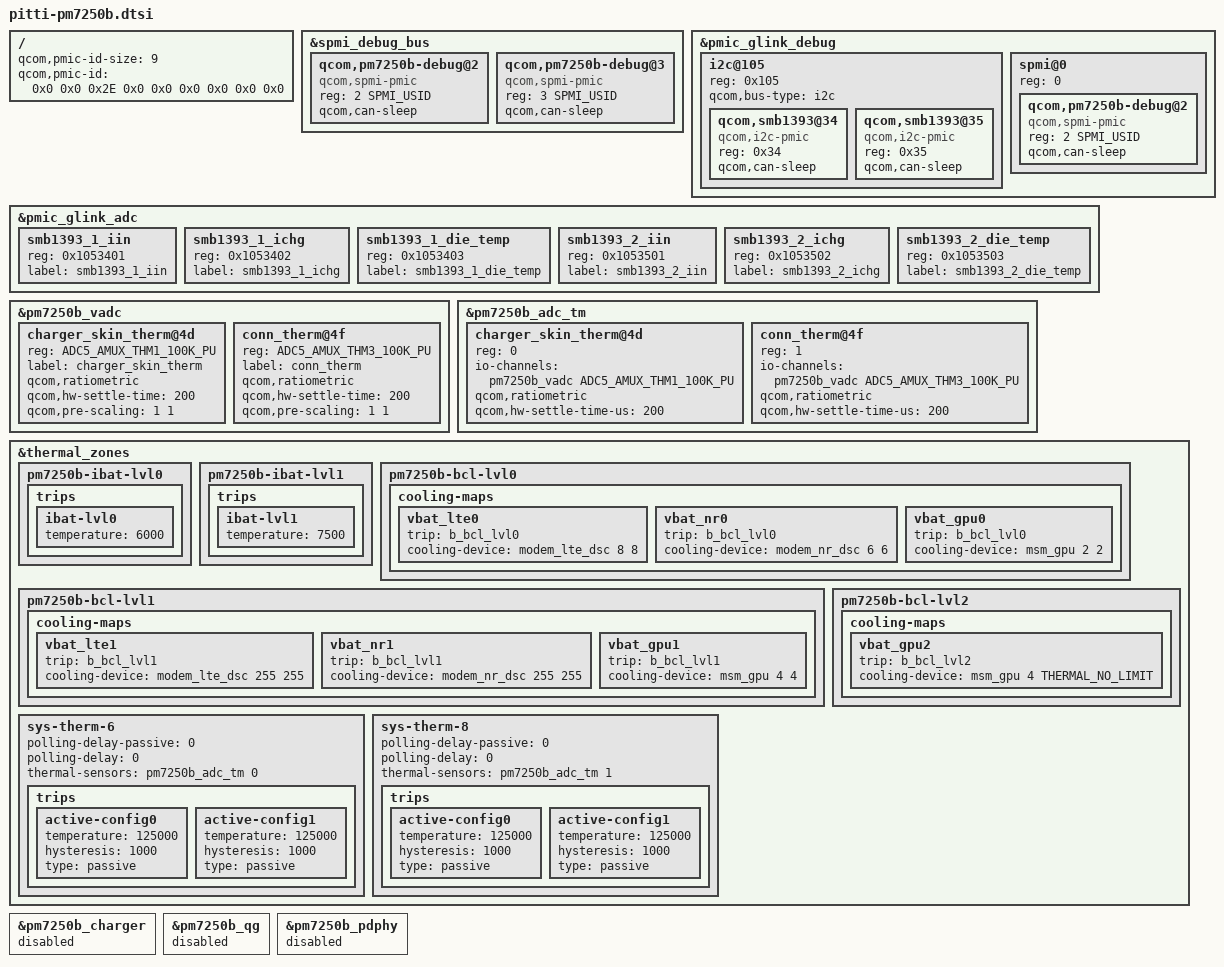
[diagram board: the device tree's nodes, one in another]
#include "pm7250b.dtsi"
#include <dt-bindings/thermal/thermal.h>

/ {
	qcom,pmic-id-size = <9>;
	qcom,pmic-id = <0x0 0x0 0x2E 0x0 0x0 0x0 0x0 0x0 0x0>;
};

&spmi_debug_bus {
	qcom,pm7250b-debug@2 {
		compatible = "qcom,spmi-pmic";
		reg = <2 SPMI_USID>;
		#address-cells = <2>;
		#size-cells = <0>;
		qcom,can-sleep;
	};

	qcom,pm7250b-debug@3 {
		compatible = "qcom,spmi-pmic";
		reg = <3 SPMI_USID>;
		#address-cells = <2>;
		#size-cells = <0>;
		qcom,can-sleep;
	};
};

&pmic_glink_debug {
	i2c@105 {
		reg = <0x105>; /* I2C instance 5 in ADSP for SE4 */
		#address-cells = <1>;
		#size-cells = <0>;
		qcom,bus-type = "i2c";

		qcom,smb1393@34 {
			compatible = "qcom,i2c-pmic";
			reg = <0x34>;
			qcom,can-sleep;
		};

		qcom,smb1393@35 {
			compatible = "qcom,i2c-pmic";
			reg = <0x35>;
			qcom,can-sleep;
		};
	};

	spmi@0 {
		reg = <0>;
		#address-cells = <2>;
		#size-cells = <0>;
		qcom,pm7250b-debug@2 {
			compatible = "qcom,spmi-pmic";
			reg = <2 SPMI_USID>;
			qcom,can-sleep;
		};
	};
};

&pmic_glink_adc {
	status = "ok";

	smb1393_1_iin {
		reg = <0x1053401>;
		label = "smb1393_1_iin";
	};

	smb1393_1_ichg {
		reg = <0x1053402>;
		label = "smb1393_1_ichg";
	};

	smb1393_1_die_temp {
		reg = <0x1053403>;
		label = "smb1393_1_die_temp";
	};

	smb1393_2_iin {
		reg = <0x1053501>;
		label = "smb1393_2_iin";
	};

	smb1393_2_ichg {
		reg = <0x1053502>;
		label = "smb1393_2_ichg";
	};

	smb1393_2_die_temp {
		reg = <0x1053503>;
		label = "smb1393_2_die_temp";
	};
};

&pm7250b_vadc {
	charger_skin_therm@4d {
		reg = <ADC5_AMUX_THM1_100K_PU>;
		label = "charger_skin_therm";
		qcom,ratiometric;
		qcom,hw-settle-time = <200>;
		qcom,pre-scaling = <1 1>;
	};

	conn_therm@4f {
		reg = <ADC5_AMUX_THM3_100K_PU>;
		label = "conn_therm";
		qcom,ratiometric;
		qcom,hw-settle-time = <200>;
		qcom,pre-scaling = <1 1>;
	};
};

&pm7250b_adc_tm {
	/* Channel nodes */
	charger_skin_therm@4d {
		reg = <0>;
		io-channels = <&pm7250b_vadc ADC5_AMUX_THM1_100K_PU>;
		qcom,ratiometric;
		qcom,hw-settle-time-us = <200>;
	};

	conn_therm@4f {
		reg = <1>;
		io-channels = <&pm7250b_vadc ADC5_AMUX_THM3_100K_PU>;
		qcom,ratiometric;
		qcom,hw-settle-time-us = <200>;
	};
};

&thermal_zones {
	pm7250b-ibat-lvl0 {
		trips {
			ibat-lvl0 {
				temperature = <6000>;
			};
		};
	};

	pm7250b-ibat-lvl1 {
		trips {
			ibat-lvl1 {
				temperature = <7500>;
			};
		};
	};

	pm7250b-bcl-lvl0 {
		cooling-maps {
			vbat_lte0 {
				trip = <&b_bcl_lvl0>;
				cooling-device = <&modem_lte_dsc 8 8>;
			};

			vbat_nr0 {
				trip = <&b_bcl_lvl0>;
				cooling-device = <&modem_nr_dsc 6 6>;
			};

			vbat_gpu0 {
				trip = <&b_bcl_lvl0>;
				cooling-device = <&msm_gpu 2 2>;
			};
		};
	};

	pm7250b-bcl-lvl1 {
		cooling-maps {
			vbat_lte1 {
				trip = <&b_bcl_lvl1>;
				cooling-device = <&modem_lte_dsc 255 255>;
			};

			vbat_nr1 {
				trip = <&b_bcl_lvl1>;
				cooling-device = <&modem_nr_dsc 255 255>;
			};

			vbat_gpu1 {
				trip = <&b_bcl_lvl1>;
				cooling-device = <&msm_gpu 4 4>;
			};
		};
	};

	pm7250b-bcl-lvl2 {
		cooling-maps {
			vbat_gpu2 {
				trip = <&b_bcl_lvl2>;
				cooling-device = <&msm_gpu 4 THERMAL_NO_LIMIT>;
			};
		};
	};

	sys-therm-6 {
		polling-delay-passive = <0>;
		polling-delay = <0>;
		thermal-sensors = <&pm7250b_adc_tm 0>;
		trips {
			active-config0 {
				temperature = <125000>;
				hysteresis = <1000>;
				type = "passive";
			};

			active-config1 {
				temperature = <125000>;
				hysteresis = <1000>;
				type = "passive";
			};
		};
	};

	sys-therm-8 {
		polling-delay-passive = <0>;
		polling-delay = <0>;
		thermal-sensors = <&pm7250b_adc_tm 1>;
		trips {
			active-config0 {
				temperature = <125000>;
				hysteresis = <1000>;
				type = "passive";
			};

			active-config1 {
				temperature = <125000>;
				hysteresis = <1000>;
				type = "passive";
			};
		};
	};
};

/* Below peripherals are supported over ADSP Glink */
&pm7250b_charger {
	status = "disabled";
};

&pm7250b_qg {
	status = "disabled";
};

&pm7250b_pdphy {
	status = "disabled";
};

